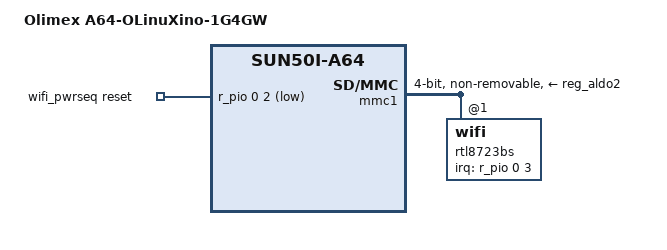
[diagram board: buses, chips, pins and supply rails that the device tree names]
/*
 * Copyright (C) 2017 Jagan Teki <jteki@openedev.com>
 *
 * This file is dual-licensed: you can use it either under the terms
 * of the GPL or the X11 license, at your option. Note that this dual
 * licensing only applies to this file, and not this project as a
 * whole.
 *
 *  a) This library is free software; you can redistribute it and/or
 *     modify it under the terms of the GNU General Public License as
 *     published by the Free Software Foundation; either version 2 of the
 *     License, or (at your option) any later version.
 *
 *     This library is distributed in the hope that it will be useful,
 *     but WITHOUT ANY WARRANTY; without even the implied warranty of
 *     MERCHANTABILITY or FITNESS FOR A PARTICULAR PURPOSE.  See the
 *     GNU General Public License for more details.
 *
 * Or, alternatively,
 *
 *  b) Permission is hereby granted, free of charge, to any person
 *     obtaining a copy of this software and associated documentation
 *     files (the "Software"), to deal in the Software without
 *     restriction, including without limitation the rights to use,
 *     copy, modify, merge, publish, distribute, sublicense, and/or
 *     sell copies of the Software, and to permit persons to whom the
 *     Software is furnished to do so, subject to the following
 *     conditions:
 *
 *     The above copyright notice and this permission notice shall be
 *     included in all copies or substantial portions of the Software.
 *
 *     THE SOFTWARE IS PROVIDED "AS IS", WITHOUT WARRANTY OF ANY KIND,
 *     EXPRESS OR IMPLIED, INCLUDING BUT NOT LIMITED TO THE WARRANTIES
 *     OF MERCHANTABILITY, FITNESS FOR A PARTICULAR PURPOSE AND
 *     NONINFRINGEMENT. IN NO EVENT SHALL THE AUTHORS OR COPYRIGHT
 *     HOLDERS BE LIABLE FOR ANY CLAIM, DAMAGES OR OTHER LIABILITY,
 *     WHETHER IN AN ACTION OF CONTRACT, TORT OR OTHERWISE, ARISING
 *     FROM, OUT OF OR IN CONNECTION WITH THE SOFTWARE OR THE USE OR
 *     OTHER DEALINGS IN THE SOFTWARE.
 */

/dts-v1/;

#include "sun50i-a64-olinuxino-2g16g-ind.dts"

/ {
	model = "Olimex A64-OLinuXino-1G4GW";
	compatible = "olimex,a64-olinuxino-2g16g-ind", "allwinner,sun50i-a64";

	wifi_pwrseq: wifi_pwrseq {
		compatible = "mmc-pwrseq-simple";
		reset-gpios = <&r_pio 0 2 GPIO_ACTIVE_LOW>; /* PL2 */
	};
};

&mmc1 {
	pinctrl-names = "default";
	pinctrl-0 = <&mmc1_pins>;
	vmmc-supply = <&reg_aldo2>;
	vqmmc-supply = <&reg_dldo4>;
	mmc-pwrseq = <&wifi_pwrseq>;
	bus-width = <4>;
	non-removable;
	status = "okay";

	rtl8723bs: wifi@1 {
		reg = <1>;
		interrupt-parent = <&r_pio>;
		interrupts = <0 3 IRQ_TYPE_LEVEL_LOW>; /* PL3 */
		interrupt-names = "host-wake";
	};
};
